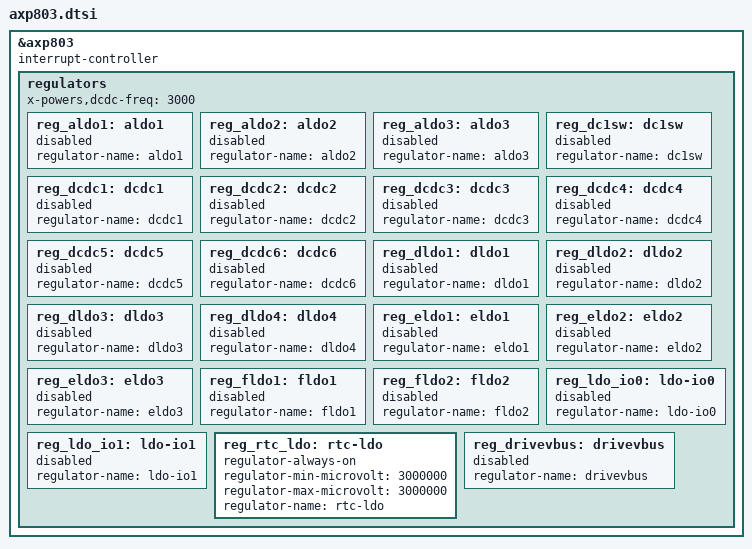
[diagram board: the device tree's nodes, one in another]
/*
 * Copyright 2017 Icenowy Zheng <icenowy@aosc.xyz>
 *
 * This file is dual-licensed: you can use it either under the terms
 * of the GPL or the X11 license, at your option. Note that this dual
 * licensing only applies to this file, and not this project as a
 * whole.
 *
 *  a) This file is free software; you can redistribute it and/or
 *     modify it under the terms of the GNU General Public License as
 *     published by the Free Software Foundation; either version 2 of the
 *     License, or (at your option) any later version.
 *
 *     This file is distributed in the hope that it will be useful,
 *     but WITHOUT ANY WARRANTY; without even the implied warranty of
 *     MERCHANTABILITY or FITNESS FOR A PARTICULAR PURPOSE.  See the
 *     GNU General Public License for more details.
 *
 * Or, alternatively,
 *
 *  b) Permission is hereby granted, free of charge, to any person
 *     obtaining a copy of this software and associated documentation
 *     files (the "Software"), to deal in the Software without
 *     restriction, including without limitation the rights to use,
 *     copy, modify, merge, publish, distribute, sublicense, and/or
 *     sell copies of the Software, and to permit persons to whom the
 *     Software is furnished to do so, subject to the following
 *     conditions:
 *
 *     The above copyright notice and this permission notice shall be
 *     included in all copies or substantial portions of the Software.
 *
 *     THE SOFTWARE IS PROVIDED "AS IS", WITHOUT WARRANTY OF ANY KIND,
 *     EXPRESS OR IMPLIED, INCLUDING BUT NOT LIMITED TO THE WARRANTIES
 *     OF MERCHANTABILITY, FITNESS FOR A PARTICULAR PURPOSE AND
 *     NONINFRINGEMENT. IN NO EVENT SHALL THE AUTHORS OR COPYRIGHT
 *     HOLDERS BE LIABLE FOR ANY CLAIM, DAMAGES OR OTHER LIABILITY,
 *     WHETHER IN AN ACTION OF CONTRACT, TORT OR OTHERWISE, ARISING
 *     FROM, OUT OF OR IN CONNECTION WITH THE SOFTWARE OR THE USE OR
 *     OTHER DEALINGS IN THE SOFTWARE.
 */

/*
 * AXP803 Integrated Power Management Chip
 * http://files.pine64.org/doc/datasheet/pine64/AXP803_Datasheet_V1.0.pdf
 */

&axp803 {
	interrupt-controller;
	#interrupt-cells = <1>;

	regulators {
		/* Default work frequency for buck regulators */
		x-powers,dcdc-freq = <3000>;

		reg_aldo1: aldo1 {
			regulator-name = "aldo1";
			status = "disabled";
		};

		reg_aldo2: aldo2 {
			regulator-name = "aldo2";
			status = "disabled";
		};

		reg_aldo3: aldo3 {
			regulator-name = "aldo3";
			status = "disabled";
		};

		reg_dc1sw: dc1sw {
			regulator-name = "dc1sw";
			status = "disabled";
		};

		reg_dcdc1: dcdc1 {
			regulator-name = "dcdc1";
			status = "disabled";
		};

		reg_dcdc2: dcdc2 {
			regulator-name = "dcdc2";
			status = "disabled";
		};

		reg_dcdc3: dcdc3 {
			regulator-name = "dcdc3";
			status = "disabled";
		};

		reg_dcdc4: dcdc4 {
			regulator-name = "dcdc4";
			status = "disabled";
		};

		reg_dcdc5: dcdc5 {
			regulator-name = "dcdc5";
			status = "disabled";
		};

		reg_dcdc6: dcdc6 {
			regulator-name = "dcdc6";
			status = "disabled";
		};

		reg_dldo1: dldo1 {
			regulator-name = "dldo1";
			status = "disabled";
		};

		reg_dldo2: dldo2 {
			regulator-name = "dldo2";
			status = "disabled";
		};

		reg_dldo3: dldo3 {
			regulator-name = "dldo3";
			status = "disabled";
		};

		reg_dldo4: dldo4 {
			regulator-name = "dldo4";
			status = "disabled";
		};

		reg_eldo1: eldo1 {
			regulator-name = "eldo1";
			status = "disabled";
		};

		reg_eldo2: eldo2 {
			regulator-name = "eldo2";
			status = "disabled";
		};

		reg_eldo3: eldo3 {
			regulator-name = "eldo3";
			status = "disabled";
		};

		reg_fldo1: fldo1 {
			regulator-name = "fldo1";
			status = "disabled";
		};

		reg_fldo2: fldo2 {
			regulator-name = "fldo2";
			status = "disabled";
		};

		reg_ldo_io0: ldo-io0 {
			regulator-name = "ldo-io0";
			status = "disabled";
		};

		reg_ldo_io1: ldo-io1 {
			regulator-name = "ldo-io1";
			status = "disabled";
		};

		reg_rtc_ldo: rtc-ldo {
			/* RTC_LDO is a fixed, always-on regulator */
			regulator-always-on;
			regulator-min-microvolt = <3000000>;
			regulator-max-microvolt = <3000000>;
			regulator-name = "rtc-ldo";
		};

		reg_drivevbus: drivevbus {
			regulator-name = "drivevbus";
			status = "disabled";
		};
	};
};
